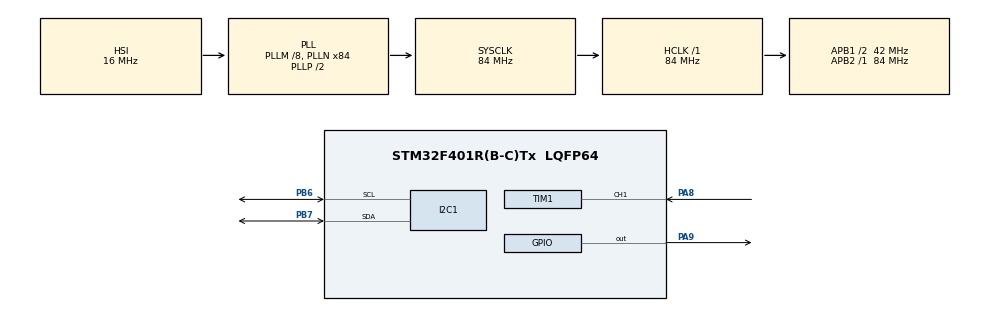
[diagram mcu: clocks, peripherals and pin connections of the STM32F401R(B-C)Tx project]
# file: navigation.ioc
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I2C1.I2C_Mode=I2C_Standard
Mcu.Family=STM32F4
Mcu.Name=STM32F401R(B-C)Tx
Mcu.Package=LQFP64
NVIC.PriorityGroup=NVIC_PRIORITYGROUP_4
NVIC.TIM1_CC_IRQn=true\:0\:0\:false\:false\:true\:true\:true\:true
PA8.Signal=S_TIM1_CH1
PA9.Signal=GPIO_Output
PB6.Mode=I2C
PB6.Signal=I2C1_SCL
PB7.Mode=I2C
PB7.Signal=I2C1_SDA
ProjectManager.HeapSize=0x200
ProjectManager.StackSize=0x400
ProjectManager.TargetToolchain=STM32CubeIDE
RCC.48MHZClocksFreq_Value=42000000
RCC.AHBFreq_Value=84000000
RCC.APB1CLKDivider=RCC_HCLK_DIV2
RCC.APB1Freq_Value=42000000
RCC.APB1TimFreq_Value=84000000
RCC.APB2Freq_Value=84000000
RCC.APB2TimFreq_Value=84000000
RCC.CortexFreq_Value=84000000
RCC.HCLKFreq_Value=84000000
RCC.HSE_VALUE=25000000
RCC.HSI_VALUE=16000000
RCC.LSE_VALUE=32768
RCC.PLLM=8
RCC.PLLN=84
RCC.SYSCLKFreq_VALUE=84000000
RCC.SYSCLKSource=RCC_SYSCLKSOURCE_PLLCLK
RCC.VCOOutputFreq_Value=168000000
SH.S_TIM1_CH1.0=TIM1_CH1,Input_Capture1_from_TI1
TIM1.Channel-Input_Capture1_from_TI1=TIM_CHANNEL_1
TIM1.Prescaler=84-1
board=custom

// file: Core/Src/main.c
/* USER CODE BEGIN Header */
/**
  ******************************************************************************
  * @file           : main.c
  * @brief          : Main program body
  ******************************************************************************
  * @attention
  *
  * Copyright (c) 2025 STMicroelectronics.
  * All rights reserved.
  *
  * This software is licensed under terms that can be found in the LICENSE file
  * in the root directory of this software component.
  * If no LICENSE file comes with this software, it is provided AS-IS.
  *
  ******************************************************************************
  */
/* USER CODE END Header */
#include "main.h"
#include "i2c.h"
#include "tim.h"
#include "gpio.h"
#include "MPU6050.h"
#include "UltraSonic.h"
/* USER CODE BEGIN Includes */

void DataHandeler(void *vPR){
	MPU6050Data receivedData;
	float dis;
	while(1){
	 if (xQueueReceive(MPU6050Queue, &receivedData, portMAX_DELAY) == pdTRUE || xQueueReceive(ultrasonicQueue, &dis, portMAX_DELAY)==pdTRUE) {
	            printf("Accel: X=%d Y=%d Z=%d | Gyro: X=%d Y=%d Z=%d | Temp=%.2f | Distance=%.2f\r\n",
	                   receivedData.AccelX, receivedData.AccelY, receivedData.AccelZ,
	                   receivedData.GyroX, receivedData.GyroY, receivedData.GyroZ,
	                   receivedData.Temperature,dis);
	        }
	}
}

/* USER CODE END Includes */

void SystemClock_Config(void);

HAL_StatusTypeDef satat;
int main(void)
{

  /* MCU Configuration--------------------------------------------------------*/

  /* Reset of all peripherals, Initializes the Flash interface and the Systick. */
  HAL_Init();

  /* Configure the system clock */
  SystemClock_Config();

  /* Initialize all configured peripherals */
  MX_GPIO_Init();
  MX_TIM1_Init();
  MX_I2C1_Init();
  /* USER CODE BEGIN 2 */
  MPU6050_Init(&hi2c1);

  MPU6050_init_task();
  Ultrasonic_Start();
  xTaskCreate(DataHandeler, "handel data", 200, NULL, 2, NULL);
  vTaskStartScheduler();
  // Create Queue

  /* USER CODE END 2 */

  /* Infinite loop */
  while (1)
  {

  }
}

void SystemClock_Config(void)
{
  RCC_OscInitTypeDef RCC_OscInitStruct = {0};
  RCC_ClkInitTypeDef RCC_ClkInitStruct = {0};

  /** Configure the main internal regulator output voltage
  */
  __HAL_RCC_PWR_CLK_ENABLE();
  __HAL_PWR_VOLTAGESCALING_CONFIG(PWR_REGULATOR_VOLTAGE_SCALE2);

  /** Initializes the RCC Oscillators according to the specified parameters
  * in the RCC_OscInitTypeDef structure.
  */
  RCC_OscInitStruct.OscillatorType = RCC_OSCILLATORTYPE_HSI;
  RCC_OscInitStruct.HSIState = RCC_HSI_ON;
  RCC_OscInitStruct.HSICalibrationValue = RCC_HSICALIBRATION_DEFAULT;
  RCC_OscInitStruct.PLL.PLLState = RCC_PLL_ON;
  RCC_OscInitStruct.PLL.PLLSource = RCC_PLLSOURCE_HSI;
  RCC_OscInitStruct.PLL.PLLM = 8;
  RCC_OscInitStruct.PLL.PLLN = 84;
  RCC_OscInitStruct.PLL.PLLP = RCC_PLLP_DIV2;
  RCC_OscInitStruct.PLL.PLLQ = 4;
  if (HAL_RCC_OscConfig(&RCC_OscInitStruct) != HAL_OK)
  {
    Error_Handler();
  }

  /** Initializes the CPU, AHB and APB buses clocks
  */
  RCC_ClkInitStruct.ClockType = RCC_CLOCKTYPE_HCLK|RCC_CLOCKTYPE_SYSCLK
                              |RCC_CLOCKTYPE_PCLK1|RCC_CLOCKTYPE_PCLK2;
  RCC_ClkInitStruct.SYSCLKSource = RCC_SYSCLKSOURCE_PLLCLK;
  RCC_ClkInitStruct.AHBCLKDivider = RCC_SYSCLK_DIV1;
  RCC_ClkInitStruct.APB1CLKDivider = RCC_HCLK_DIV2;
  RCC_ClkInitStruct.APB2CLKDivider = RCC_HCLK_DIV1;

  if (HAL_RCC_ClockConfig(&RCC_ClkInitStruct, FLASH_LATENCY_2) != HAL_OK)
  {
    Error_Handler();
  }
}

void Error_Handler(void)
{
  __disable_irq();
  while (1)
  {
  }
}
